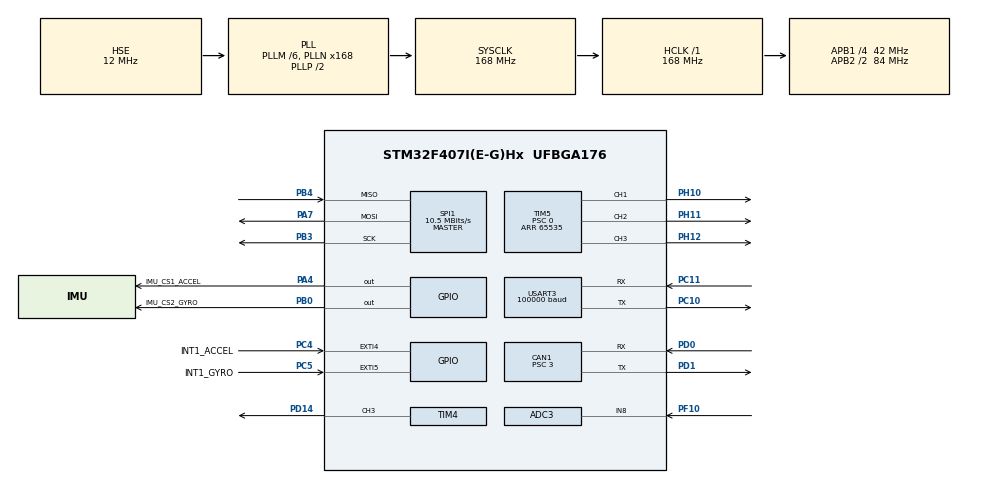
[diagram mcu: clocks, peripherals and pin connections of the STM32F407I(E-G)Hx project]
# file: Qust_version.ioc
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ADC3.Channel-1\#ChannelRegularConversion=ADC_CHANNEL_8
ADC3.NbrOfConversionFlag=1
ADC3.Rank-1\#ChannelRegularConversion=1
ADC3.SamplingTime-1\#ChannelRegularConversion=ADC_SAMPLETIME_3CYCLES
CAN1.BS1=CAN_BS1_12TQ
CAN1.CalculateBaudRate=1000000
CAN1.CalculateTimeBit=1000
CAN1.CalculateTimeQuantum=71.42857142857143
CAN1.Prescaler=3
Dma.Request0=USART3_RX
Dma.USART3_RX.0.Direction=DMA_PERIPH_TO_MEMORY
Dma.USART3_RX.0.FIFOMode=DMA_FIFOMODE_DISABLE
Dma.USART3_RX.0.Instance=DMA1_Stream1
Dma.USART3_RX.0.MemDataAlignment=DMA_MDATAALIGN_BYTE
Dma.USART3_RX.0.MemInc=DMA_MINC_ENABLE
Dma.USART3_RX.0.Mode=DMA_CIRCULAR
Dma.USART3_RX.0.PeriphDataAlignment=DMA_PDATAALIGN_BYTE
Dma.USART3_RX.0.PeriphInc=DMA_PINC_DISABLE
Dma.USART3_RX.0.Priority=DMA_PRIORITY_HIGH
FREERTOS.Tasks01=RAMMER,1,256,rammer_task,As weak,NULL,Dynamic,NULL,NULL
FREERTOS.configMAX_PRIORITIES=16
Mcu.Family=STM32F4
Mcu.Name=STM32F407I(E-G)Hx
Mcu.Package=UFBGA176
NVIC.CAN1_RX0_IRQn=true\:5\:0\:false\:false\:true\:true\:true\:true\:true
NVIC.DMA1_Stream1_IRQn=true\:5\:0\:false\:false\:true\:false\:true\:true\:true
NVIC.EXTI4_IRQn=true\:5\:0\:false\:false\:true\:true\:true\:true\:true
NVIC.EXTI9_5_IRQn=true\:5\:0\:false\:false\:true\:true\:true\:true\:true
NVIC.PriorityGroup=NVIC_PRIORITYGROUP_4
NVIC.TIM1_UP_TIM10_IRQn=true\:15\:0\:false\:false\:true\:false\:false\:true\:true
NVIC.TimeBase=TIM1_UP_TIM10_IRQn
NVIC.TimeBaseIP=TIM1
NVIC.USART3_IRQn=true\:5\:0\:false\:false\:true\:true\:true\:true\:true
PA13.Mode=Serial_Wire
PA13.Signal=SYS_JTMS-SWDIO
PA14.Mode=Serial_Wire
PA14.Signal=SYS_JTCK-SWCLK
PA4.GPIO_Label=IMU_CS1_ACCEL
PA4.GPIO_PuPd=GPIO_PULLUP
PA4.PinState=GPIO_PIN_SET
PA4.Signal=GPIO_Output
PA7.Mode=Full_Duplex_Master
PA7.Signal=SPI1_MOSI
PB0.GPIO_Label=IMU_CS2_GYRO
PB0.GPIO_PuPd=GPIO_PULLUP
PB0.PinState=GPIO_PIN_SET
PB0.Signal=GPIO_Output
PB3.Mode=Full_Duplex_Master
PB3.Signal=SPI1_SCK
PB4.Mode=Full_Duplex_Master
PB4.Signal=SPI1_MISO
PC10.Mode=Asynchronous
PC10.Signal=USART3_TX
PC11.Mode=Asynchronous
PC11.Signal=USART3_RX
PC4.GPIO_Label=INT1_ACCEL
PC4.Signal=GPXTI4
PC5.GPIO_Label=INT1_GYRO
PC5.Signal=GPXTI5
PD0.Mode=CAN_Activate
PD0.Signal=CAN1_RX
PD1.Mode=CAN_Activate
PD1.Signal=CAN1_TX
PD14.Signal=S_TIM4_CH3
PF10.Mode=IN8
PF10.Signal=ADC3_IN8
PH0-OSC_IN.Mode=HSE-External-Oscillator
PH0-OSC_IN.Signal=RCC_OSC_IN
PH1-OSC_OUT.Mode=HSE-External-Oscillator
PH1-OSC_OUT.Signal=RCC_OSC_OUT
PH10.Signal=S_TIM5_CH1
PH11.Signal=S_TIM5_CH2
PH12.Signal=S_TIM5_CH3
ProjectManager.HeapSize=0x200
ProjectManager.StackSize=0x400
ProjectManager.TargetToolchain=CMake
RCC.48MHZClocksFreq_Value=84000000
RCC.AHBFreq_Value=168000000
RCC.APB1CLKDivider=RCC_HCLK_DIV4
RCC.APB1Freq_Value=42000000
RCC.APB1TimFreq_Value=84000000
RCC.APB2CLKDivider=RCC_HCLK_DIV2
RCC.APB2Freq_Value=84000000
RCC.APB2TimFreq_Value=168000000
RCC.CortexFreq_Value=168000000
RCC.HCLKFreq_Value=168000000
RCC.HSE_VALUE=12000000
RCC.HSI_VALUE=16000000
RCC.LSE_VALUE=32768
RCC.PLLM=6
RCC.PLLN=168
RCC.PLLSourceVirtual=RCC_PLLSOURCE_HSE
RCC.SYSCLKFreq_VALUE=168000000
RCC.SYSCLKSource=RCC_SYSCLKSOURCE_PLLCLK
RCC.VCOOutputFreq_Value=336000000
SH.S_TIM4_CH3.0=TIM4_CH3,PWM Generation3 CH3
SH.S_TIM5_CH1.0=TIM5_CH1,PWM Generation1 CH1
SH.S_TIM5_CH2.0=TIM5_CH2,PWM Generation2 CH2
SH.S_TIM5_CH3.0=TIM5_CH3,PWM Generation3 CH3
SPI1.BaudRatePrescaler=SPI_BAUDRATEPRESCALER_8
SPI1.CLKPhase=SPI_PHASE_2EDGE
SPI1.CLKPolarity=SPI_POLARITY_HIGH
SPI1.CalculateBaudRate=10.5 MBits/s
SPI1.Direction=SPI_DIRECTION_2LINES
SPI1.Mode=SPI_MODE_MASTER
SPI1.VirtualType=VM_MASTER
TIM4.Channel-PWM\ Generation3\ CH3=TIM_CHANNEL_3
TIM4.Period=65535
TIM4.Prescaler=0
TIM5.Channel-PWM\ Generation1\ CH1=TIM_CHANNEL_1
TIM5.Channel-PWM\ Generation2\ CH2=TIM_CHANNEL_2
TIM5.Channel-PWM\ Generation3\ CH3=TIM_CHANNEL_3
TIM5.Period=65535
TIM5.Prescaler=0
USART3.BaudRate=100000
USART3.Parity=PARITY_EVEN
USART3.VirtualMode=VM_ASYNC
USART3.WordLength=WORDLENGTH_9B
VP_FREERTOS_VS_CMSIS_V1.Mode=CMSIS_V1
VP_SYS_VS_tim1.Mode=TIM1
board=custom

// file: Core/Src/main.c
/* USER CODE BEGIN Header */
/**
  ******************************************************************************
  * @file           : main.c
  * @brief          : Main program body
  ******************************************************************************
  * @attention
  *
  * Copyright (c) 2026 STMicroelectronics.
  * All rights reserved.
  *
  * This software is licensed under terms that can be found in the LICENSE file
  * in the root directory of this software component.
  * If no LICENSE file comes with this software, it is provided AS-IS.
  *
  ******************************************************************************
  */
/* USER CODE END Header */
#include "main.h"
#include "cmsis_os.h"
#include "adc.h"
#include "can.h"
#include "dma.h"
#include "spi.h"
#include "tim.h"
#include "usart.h"
#include "gpio.h"

void SystemClock_Config(void);
void MX_FREERTOS_Init(void);

int main(void)
{

  /* MCU Configuration--------------------------------------------------------*/

  /* Reset of all peripherals, Initializes the Flash interface and the Systick. */
  HAL_Init();

  /* Configure the system clock */
  SystemClock_Config();

  /* Initialize all configured peripherals */
  MX_GPIO_Init();
  MX_DMA_Init();
  MX_CAN1_Init();
  MX_SPI1_Init();
  MX_TIM4_Init();
  MX_TIM5_Init();
  MX_USART3_UART_Init();
  MX_ADC3_Init();

  /* Call init function for freertos objects (in cmsis_os2.c) */
  MX_FREERTOS_Init();

  /* Start scheduler */
  osKernelStart();

  /* We should never get here as control is now taken by the scheduler */

  /* Infinite loop */
  while (1)
  {

  }
}

void SystemClock_Config(void)
{
  RCC_OscInitTypeDef RCC_OscInitStruct = {0};
  RCC_ClkInitTypeDef RCC_ClkInitStruct = {0};

  /** Configure the main internal regulator output voltage
  */
  __HAL_RCC_PWR_CLK_ENABLE();
  __HAL_PWR_VOLTAGESCALING_CONFIG(PWR_REGULATOR_VOLTAGE_SCALE1);

  /** Initializes the RCC Oscillators according to the specified parameters
  * in the RCC_OscInitTypeDef structure.
  */
  RCC_OscInitStruct.OscillatorType = RCC_OSCILLATORTYPE_HSE;
  RCC_OscInitStruct.HSEState = RCC_HSE_ON;
  RCC_OscInitStruct.PLL.PLLState = RCC_PLL_ON;
  RCC_OscInitStruct.PLL.PLLSource = RCC_PLLSOURCE_HSE;
  RCC_OscInitStruct.PLL.PLLM = 6;
  RCC_OscInitStruct.PLL.PLLN = 168;
  RCC_OscInitStruct.PLL.PLLP = RCC_PLLP_DIV2;
  RCC_OscInitStruct.PLL.PLLQ = 4;
  if (HAL_RCC_OscConfig(&RCC_OscInitStruct) != HAL_OK)
  {
    Error_Handler();
  }

  /** Initializes the CPU, AHB and APB buses clocks
  */
  RCC_ClkInitStruct.ClockType = RCC_CLOCKTYPE_HCLK|RCC_CLOCKTYPE_SYSCLK
                              |RCC_CLOCKTYPE_PCLK1|RCC_CLOCKTYPE_PCLK2;
  RCC_ClkInitStruct.SYSCLKSource = RCC_SYSCLKSOURCE_PLLCLK;
  RCC_ClkInitStruct.AHBCLKDivider = RCC_SYSCLK_DIV1;
  RCC_ClkInitStruct.APB1CLKDivider = RCC_HCLK_DIV4;
  RCC_ClkInitStruct.APB2CLKDivider = RCC_HCLK_DIV2;

  if (HAL_RCC_ClockConfig(&RCC_ClkInitStruct, FLASH_LATENCY_5) != HAL_OK)
  {
    Error_Handler();
  }
}

void HAL_TIM_PeriodElapsedCallback(TIM_HandleTypeDef *htim)
{
  if (htim->Instance == TIM1)
  {
    HAL_IncTick();
  }
}

void Error_Handler(void)
{
  /* USER CODE BEGIN Error_Handler_Debug */
  /* User can add his own implementation to report the HAL error return state */
  // [解析] __disable_irq() 关掉所有中断（除了 NMI 和 HardFault），
  // [解析] 然后死循环。这是一种"安全停机"：宁可停住，也不要带着错误继续控制电机。
  // [解析] 常见触发原因：晶振没起振、引脚被别的外设占用、时钟树配置非法。
  __disable_irq();
  while (1)
  {
  }
  /* USER CODE END Error_Handler_Debug */
}

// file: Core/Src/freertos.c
/* USER CODE BEGIN Header */
/**
  ******************************************************************************
  * File Name          : freertos.c
  * Description        : Code for freertos applications
  ******************************************************************************
  * @attention
  *
  * Copyright (c) 2026 STMicroelectronics.
  * All rights reserved.
  *
  * This software is licensed under terms that can be found in the LICENSE file
  * in the root directory of this software component.
  * If no LICENSE file comes with this software, it is provided AS-IS.
  *
  ******************************************************************************
  */
/* USER CODE END Header */

#include "FreeRTOS.h"
#include "task.h"
#include "main.h"
#include "cmsis_os.h"

osThreadId RAMMERHandle;

void rammer_task(void const * argument);

void MX_FREERTOS_Init(void); /* (MISRA C 2004 rule 8.1) */

/* GetIdleTaskMemory prototype (linked to static allocation support) */
void vApplicationGetIdleTaskMemory( StaticTask_t **ppxIdleTaskTCBBuffer, StackType_t **ppxIdleTaskStackBuffer, uint32_t *pulIdleTaskStackSize );

/* USER CODE BEGIN GET_IDLE_TASK_MEMORY */
// [解析] ★ 这段是"给空闲任务静态分配内存"。
// [解析]   背景：FreeRTOS 里必然存在一个优先级为 0 的"空闲任务"(Idle Task)，
// [解析]   它的作用是"当所有任务都在延时/等待时，让 CPU 有事可做（并回收被删除任务的内存）"。
// [解析]   本工程在 FreeRTOSConfig.h 里同时打开了"静态分配"和"动态分配"
// [解析]   （configSUPPORT_STATIC_ALLOCATION = 1）。
// [解析]   一旦打开静态分配，FreeRTOS 就要求你【必须】自己提供空闲任务的内存
// [解析]   —— 也就是下面这两个数组；否则编译时会报缺少
// [解析]   vApplicationGetIdleTaskMemory 的链接错误。
// [解析]   好处是：空闲任务的内存不再从 heap 里分配，是编译期就确定的静态数组，
// [解析]   不会因为堆碎片或堆不够而创建失败。
static StaticTask_t xIdleTaskTCBBuffer;
// [解析] ↑ 空闲任务的"任务控制块"(TCB)，存放任务状态、优先级等信息。
static StackType_t xIdleStack[configMINIMAL_STACK_SIZE];
// [解析] ↑ 空闲任务的栈。configMINIMAL_STACK_SIZE 在 FreeRTOSConfig.h 里是 128，
// [解析]   单位是"字"(StackType_t = 4 字节)，所以等于 512 字节。

// [解析] 这个函数由 FreeRTOS 内核自动调用（它在创建空闲任务时会来找你要内存）。
// [解析] 你只需要把上面那两个静态数组的地址"填进"输出的指针里就行。
void vApplicationGetIdleTaskMemory( StaticTask_t **ppxIdleTaskTCBBuffer, StackType_t **ppxIdleTaskStackBuffer, uint32_t *pulIdleTaskStackSize )
{
  *ppxIdleTaskTCBBuffer = &xIdleTaskTCBBuffer;
  *ppxIdleTaskStackBuffer = &xIdleStack[0];
  *pulIdleTaskStackSize = configMINIMAL_STACK_SIZE;
  /* place for user code */
}
/* USER CODE END GET_IDLE_TASK_MEMORY */

void MX_FREERTOS_Init(void) {

  /* Create the thread(s) */
  /* definition and creation of RAMMER */
  osThreadDef(RAMMER, rammer_task, osPriorityAboveNormal, 0, 256);
  RAMMERHandle = osThreadCreate(osThread(RAMMER), NULL);

}

__weak void rammer_task(void const * argument)
{
  for(;;)
  {
    osDelay(1);
  }
}
